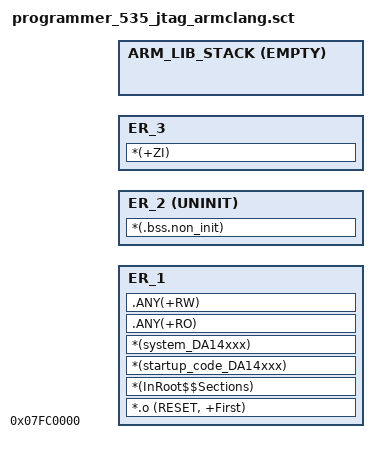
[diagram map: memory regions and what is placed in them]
#! armclang -E -I.\..\..\sdk\platform\include\ --target=arm-arm-none-eabi -mcpu=cortex-m0plus -xc

#define __DA14535__
#include "sdk_defs.h"

LR_1 0x07FC0000 9*1024 {
    ER_1 +0 {
       *.o (RESET, +First)
       *(InRoot$$Sections)
        *(startup_code_DA14xxx)
       *(system_DA14xxx)
       .ANY(+RO)
       .ANY(+RW)
    }

    ER_2 AlignExpr(+0,8) UNINIT {
       *(.bss.non_init)
    }

; The address space after 0x07FC3C00 is used by SmartSnippets Toolbox for commands and data
; and must not be overwritten by application code
    ER_3 +0 (0x07FC3C00 - ImageLimit(ER_2) - SDK_FLASH_PROGRAMMER_STACK_SIZE) {
       *(+ZI)
    }

    ; Stack region growing down
    ARM_LIB_STACK ImageLimit(ER_3) + SDK_FLASH_PROGRAMMER_STACK_SIZE EMPTY -SDK_FLASH_PROGRAMMER_STACK_SIZE {}
}

ScatterAssert(ImageLimit(ARM_LIB_STACK) < 0x07FC3C00)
